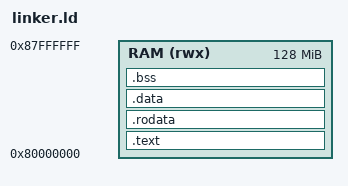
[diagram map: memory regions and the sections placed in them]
cat > linker.ld << 'EOF'
ENTRY(_start)

MEMORY
{
    RAM (rwx) : ORIGIN = 0x80000000, LENGTH = 128M
}

SECTIONS
{
    .text : { *(.text*) } > RAM
    .rodata : { *(.rodata*) } > RAM
    .data : { *(.data*) } > RAM
    .bss : { *(.bss*) *(COMMON) } > RAM

    . = ALIGN(16);
    __stack_top = ORIGIN(RAM) + LENGTH(RAM);
}
EOF
